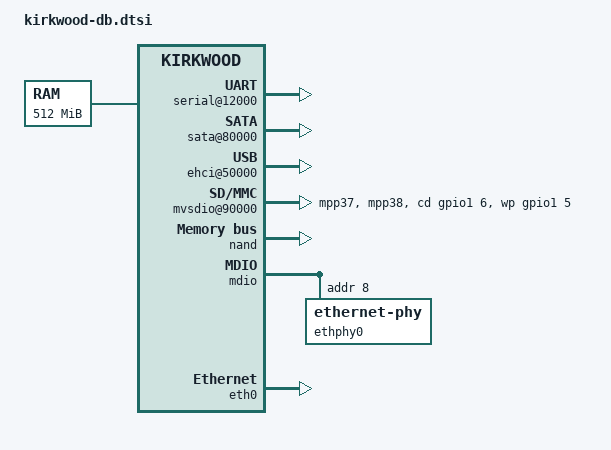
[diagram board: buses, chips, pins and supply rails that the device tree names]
#include "kirkwood.dtsi"
/ {
	memory {
		device_type = "memory";
		reg = <0x00000000 0x20000000>;  
	};
	chosen {
		bootargs = "console=ttyS0,115200n8 earlyprintk";
		stdout-path = &uart0;
	};
	ocp@f1000000 {
		pin-controller@10000 {
			pmx_sdio_gpios: pmx-sdio-gpios {
				marvell,pins = "mpp37", "mpp38";
				marvell,function = "gpio";
			};
		};
		serial@12000 {
			status = "okay";
		};
		sata@80000 {
			nr-ports = <2>;
			status = "okay";
		};
		ehci@50000 {
			status = "okay";
		};
		mvsdio@90000 {
			pinctrl-0 = <&pmx_sdio_gpios>;
			pinctrl-names = "default";
			wp-gpios = <&gpio1 5 GPIO_ACTIVE_HIGH>;
			cd-gpios = <&gpio1 6 GPIO_ACTIVE_HIGH>;
			status = "okay";
		};
	};
};
&nand {
	chip-delay = <25>;
	status = "okay";
	partition@0 {
		label = "uboot";
		reg = <0x0 0x100000>;
	};
	partition@100000 {
		label = "uImage";
		reg = <0x100000 0x400000>;
	};
	partition@500000 {
		label = "root";
		reg = <0x500000 0x1fb00000>;
	};
};
&mdio {
	status = "okay";
	ethphy0: ethernet-phy@8 {
		reg = <8>;
	};
};
&eth0 {
	status = "okay";
	ethernet0-port@0 {
		phy-handle = <&ethphy0>;
	};
};
